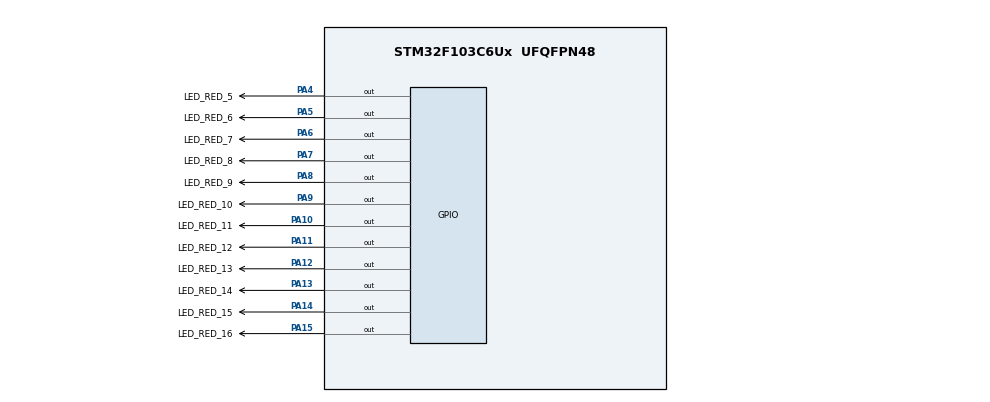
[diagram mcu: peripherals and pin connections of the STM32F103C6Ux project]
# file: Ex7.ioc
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Mcu.Family=STM32F1
Mcu.Name=STM32F103C6Ux
Mcu.Package=UFQFPN48
NVIC.PriorityGroup=NVIC_PRIORITYGROUP_4
PA10.GPIO_Label=LED_RED_11
PA10.Signal=GPIO_Output
PA11.GPIO_Label=LED_RED_12
PA11.Signal=GPIO_Output
PA12.GPIO_Label=LED_RED_13
PA12.Signal=GPIO_Output
PA13.GPIO_Label=LED_RED_14
PA13.Signal=GPIO_Output
PA14.GPIO_Label=LED_RED_15
PA14.Signal=GPIO_Output
PA15.GPIO_Label=LED_RED_16
PA15.Signal=GPIO_Output
PA4.GPIO_Label=LED_RED_5
PA4.Signal=GPIO_Output
PA5.GPIO_Label=LED_RED_6
PA5.Signal=GPIO_Output
PA6.GPIO_Label=LED_RED_7
PA6.Signal=GPIO_Output
PA7.GPIO_Label=LED_RED_8
PA7.Signal=GPIO_Output
PA8.GPIO_Label=LED_RED_9
PA8.Signal=GPIO_Output
PA9.GPIO_Label=LED_RED_10
PA9.Signal=GPIO_Output
ProjectManager.HeapSize=0x200
ProjectManager.StackSize=0x400
ProjectManager.TargetToolchain=STM32CubeIDE
RCC.APB1Freq_Value=8000000
RCC.APB2Freq_Value=8000000
VP_SYS_VS_ND.Mode=No_Debug
board=custom

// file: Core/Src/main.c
/* USER CODE BEGIN Header */
/**
  ******************************************************************************
  * @file           : main.c
  * @brief          : Main program body
  ******************************************************************************
  * @attention
  *
  * <h2><center>&copy; Copyright (c) 2024 STMicroelectronics.
  * All rights reserved.</center></h2>
  *
  * This software component is licensed by ST under BSD 3-Clause license,
  * the "License"; You may not use this file except in compliance with the
  * License. You may obtain a copy of the License at:
  *                        opensource.org/licenses/BSD-3-Clause
  *
  ******************************************************************************
  */
/* USER CODE END Header */
#include "main.h"

void SystemClock_Config(void);
static void MX_GPIO_Init(void);

void display12Led(int counter);
void clearAllClock();

int main(void)
{

  /* MCU Configuration--------------------------------------------------------*/

  /* Reset of all peripherals, Initializes the Flash interface and the Systick. */
  HAL_Init();

  /* Configure the system clock */
  SystemClock_Config();

  /* Initialize all configured peripherals */
  MX_GPIO_Init();

  /* Infinite loop */
  /* USER CODE BEGIN WHILE */
  int counter = 1;
  int limitNumber = 13;

  while (1)
  {
    /* USER CODE END WHILE */
	display12Led(counter);
	counter++;
	HAL_Delay(1000);
	if(counter == limitNumber){
		clearAllClock();
		counter = 1;
		HAL_Delay(1000);
	}
  }
}

void clearAllClock(){
	  HAL_GPIO_WritePin(LED_RED_5_GPIO_Port, LED_RED_5_Pin, GPIO_PIN_RESET);
	  HAL_GPIO_WritePin(LED_RED_6_GPIO_Port, LED_RED_6_Pin, GPIO_PIN_RESET);
	  HAL_GPIO_WritePin(LED_RED_7_GPIO_Port, LED_RED_7_Pin, GPIO_PIN_RESET);
	  HAL_GPIO_WritePin(LED_RED_8_GPIO_Port, LED_RED_8_Pin, GPIO_PIN_RESET);
	  HAL_GPIO_WritePin(LED_RED_9_GPIO_Port, LED_RED_9_Pin, GPIO_PIN_RESET);
	  HAL_GPIO_WritePin(LED_RED_10_GPIO_Port, LED_RED_10_Pin, GPIO_PIN_RESET);
	  HAL_GPIO_WritePin(LED_RED_11_GPIO_Port, LED_RED_11_Pin, GPIO_PIN_RESET);
	  HAL_GPIO_WritePin(LED_RED_12_GPIO_Port, LED_RED_12_Pin, GPIO_PIN_RESET);
	  HAL_GPIO_WritePin(LED_RED_13_GPIO_Port, LED_RED_13_Pin, GPIO_PIN_RESET);
	  HAL_GPIO_WritePin(LED_RED_14_GPIO_Port, LED_RED_14_Pin, GPIO_PIN_RESET);
	  HAL_GPIO_WritePin(LED_RED_15_GPIO_Port, LED_RED_15_Pin, GPIO_PIN_RESET);
	  HAL_GPIO_WritePin(LED_RED_16_GPIO_Port, LED_RED_16_Pin, GPIO_PIN_RESET);
}

void setNumberOnClock(int num){
	  if(counter == 1){
		  HAL_GPIO_WritePin(LED_RED_7_GPIO_Port, LED_RED_7_Pin, GPIO_PIN_SET);
	  }
	  if(counter == 2){
		  HAL_GPIO_WritePin(LED_RED_8_GPIO_Port, LED_RED_8_Pin, GPIO_PIN_SET);
	  }
	  if(counter == 3){
		  HAL_GPIO_WritePin(LED_RED_9_GPIO_Port, LED_RED_9_Pin, GPIO_PIN_SET);
	  }
	  if(counter == 4){
		  HAL_GPIO_WritePin(LED_RED_10_GPIO_Port, LED_RED_10_Pin, GPIO_PIN_SET);
	  }
	  if(counter == 5){
		  HAL_GPIO_WritePin(LED_RED_11_GPIO_Port, LED_RED_11_Pin, GPIO_PIN_SET);
	  }
	  if(counter == 6){
		  HAL_GPIO_WritePin(LED_RED_12_GPIO_Port, LED_RED_12_Pin, GPIO_PIN_SET);
	  }
	  if(counter == 7){
		  HAL_GPIO_WritePin(LED_RED_13_GPIO_Port, LED_RED_13_Pin, GPIO_PIN_SET);
	  }
	  if(counter == 8){
		  HAL_GPIO_WritePin(LED_RED_14_GPIO_Port, LED_RED_14_Pin, GPIO_PIN_SET);
	  }
	  if(counter == 9){
		  HAL_GPIO_WritePin(LED_RED_15_GPIO_Port, LED_RED_15_Pin, GPIO_PIN_SET);
	  }
	  if(counter == 10){
		  HAL_GPIO_WritePin(LED_RED_16_GPIO_Port, LED_RED_16_Pin, GPIO_PIN_SET);
	  }
	  if(counter == 11){
		  HAL_GPIO_WritePin(LED_RED_5_GPIO_Port, LED_RED_5_Pin, GPIO_PIN_SET);
	  }
	  if(counter == 12){
		  HAL_GPIO_WritePin(LED_RED_6_GPIO_Port, LED_RED_6_Pin, GPIO_PIN_SET);
	  }
}

void clearNumberOnClock(int num){
	  if(counter == 1){
		  HAL_GPIO_WritePin(LED_RED_7_GPIO_Port, LED_RED_7_Pin, GPIO_PIN_RESET);
	  }
	  if(counter == 2){
		  HAL_GPIO_WritePin(LED_RED_8_GPIO_Port, LED_RED_8_Pin, GPIO_PIN_RESET);
	  }
	  if(counter == 3){
		  HAL_GPIO_WritePin(LED_RED_9_GPIO_Port, LED_RED_9_Pin, GPIO_PIN_RESET);
	  }
	  if(counter == 4){
		  HAL_GPIO_WritePin(LED_RED_10_GPIO_Port, LED_RED_10_Pin, GPIO_PIN_RESET);
	  }
	  if(counter == 5){
		  HAL_GPIO_WritePin(LED_RED_11_GPIO_Port, LED_RED_11_Pin, GPIO_PIN_RESET);
	  }
	  if(counter == 6){
		  HAL_GPIO_WritePin(LED_RED_12_GPIO_Port, LED_RED_12_Pin, GPIO_PIN_RESET);
	  }
	  if(counter == 7){
		  HAL_GPIO_WritePin(LED_RED_13_GPIO_Port, LED_RED_13_Pin, GPIO_PIN_RESET);
	  }
	  if(counter == 8){
		  HAL_GPIO_WritePin(LED_RED_14_GPIO_Port, LED_RED_14_Pin, GPIO_PIN_RESET);
	  }
	  if(counter == 9){
		  HAL_GPIO_WritePin(LED_RED_15_GPIO_Port, LED_RED_15_Pin, GPIO_PIN_RESET);
	  }
	  if(counter == 10){
		  HAL_GPIO_WritePin(LED_RED_16_GPIO_Port, LED_RED_16_Pin, GPIO_PIN_RESET);
	  }
	  if(counter == 11){
		  HAL_GPIO_WritePin(LED_RED_5_GPIO_Port, LED_RED_5_Pin, GPIO_PIN_RESET);
	  }
	  if(counter == 12){
		  HAL_GPIO_WritePin(LED_RED_6_GPIO_Port, LED_RED_6_Pin, GPIO_PIN_RESET);
	  }
}

 void display12Led(int counter){

	  if(counter == 1){
		  HAL_GPIO_WritePin(LED_RED_5_GPIO_Port, LED_RED_5_Pin, GPIO_PIN_RESET);
		  HAL_GPIO_WritePin(LED_RED_6_GPIO_Port, LED_RED_6_Pin, GPIO_PIN_RESET);
		  HAL_GPIO_WritePin(LED_RED_7_GPIO_Port, LED_RED_7_Pin, GPIO_PIN_SET);
		  HAL_GPIO_WritePin(LED_RED_8_GPIO_Port, LED_RED_8_Pin, GPIO_PIN_RESET);
		  HAL_GPIO_WritePin(LED_RED_9_GPIO_Port, LED_RED_9_Pin, GPIO_PIN_RESET);
		  HAL_GPIO_WritePin(LED_RED_10_GPIO_Port, LED_RED_10_Pin, GPIO_PIN_RESET);
		  HAL_GPIO_WritePin(LED_RED_11_GPIO_Port, LED_RED_11_Pin, GPIO_PIN_RESET);
		  HAL_GPIO_WritePin(LED_RED_12_GPIO_Port, LED_RED_12_Pin, GPIO_PIN_RESET);
		  HAL_GPIO_WritePin(LED_RED_13_GPIO_Port, LED_RED_13_Pin, GPIO_PIN_RESET);
		  HAL_GPIO_WritePin(LED_RED_14_GPIO_Port, LED_RED_14_Pin, GPIO_PIN_RESET);
		  HAL_GPIO_WritePin(LED_RED_15_GPIO_Port, LED_RED_15_Pin, GPIO_PIN_RESET);
		  HAL_GPIO_WritePin(LED_RED_16_GPIO_Port, LED_RED_16_Pin, GPIO_PIN_RESET);
	  }
	  if(counter == 2){
		  HAL_GPIO_WritePin(LED_RED_5_GPIO_Port, LED_RED_5_Pin, GPIO_PIN_RESET);
		  HAL_GPIO_WritePin(LED_RED_6_GPIO_Port, LED_RED_6_Pin, GPIO_PIN_RESET);
		  HAL_GPIO_WritePin(LED_RED_7_GPIO_Port, LED_RED_7_Pin, GPIO_PIN_SET);
		  HAL_GPIO_WritePin(LED_RED_8_GPIO_Port, LED_RED_8_Pin, GPIO_PIN_SET);
		  HAL_GPIO_WritePin(LED_RED_9_GPIO_Port, LED_RED_9_Pin, GPIO_PIN_RESET);
		  HAL_GPIO_WritePin(LED_RED_10_GPIO_Port, LED_RED_10_Pin, GPIO_PIN_RESET);
		  HAL_GPIO_WritePin(LED_RED_11_GPIO_Port, LED_RED_11_Pin, GPIO_PIN_RESET);
		  HAL_GPIO_WritePin(LED_RED_12_GPIO_Port, LED_RED_12_Pin, GPIO_PIN_RESET);
		  HAL_GPIO_WritePin(LED_RED_13_GPIO_Port, LED_RED_13_Pin, GPIO_PIN_RESET);
		  HAL_GPIO_WritePin(LED_RED_14_GPIO_Port, LED_RED_14_Pin, GPIO_PIN_RESET);
		  HAL_GPIO_WritePin(LED_RED_15_GPIO_Port, LED_RED_15_Pin, GPIO_PIN_RESET);
		  HAL_GPIO_WritePin(LED_RED_16_GPIO_Port, LED_RED_16_Pin, GPIO_PIN_RESET);
	  }
	  if(counter == 3){
		  HAL_GPIO_WritePin(LED_RED_5_GPIO_Port, LED_RED_5_Pin, GPIO_PIN_RESET);
		  HAL_GPIO_WritePin(LED_RED_6_GPIO_Port, LED_RED_6_Pin, GPIO_PIN_RESET);
		  HAL_GPIO_WritePin(LED_RED_7_GPIO_Port, LED_RED_7_Pin, GPIO_PIN_SET);
		  HAL_GPIO_WritePin(LED_RED_8_GPIO_Port, LED_RED_8_Pin, GPIO_PIN_SET);
		  HAL_GPIO_WritePin(LED_RED_9_GPIO_Port, LED_RED_9_Pin, GPIO_PIN_SET);
		  HAL_GPIO_WritePin(LED_RED_10_GPIO_Port, LED_RED_10_Pin, GPIO_PIN_RESET);
		  HAL_GPIO_WritePin(LED_RED_11_GPIO_Port, LED_RED_11_Pin, GPIO_PIN_RESET);
		  HAL_GPIO_WritePin(LED_RED_12_GPIO_Port, LED_RED_12_Pin, GPIO_PIN_RESET);
		  HAL_GPIO_WritePin(LED_RED_13_GPIO_Port, LED_RED_13_Pin, GPIO_PIN_RESET);
		  HAL_GPIO_WritePin(LED_RED_14_GPIO_Port, LED_RED_14_Pin, GPIO_PIN_RESET);
		  HAL_GPIO_WritePin(LED_RED_15_GPIO_Port, LED_RED_15_Pin, GPIO_PIN_RESET);
		  HAL_GPIO_WritePin(LED_RED_16_GPIO_Port, LED_RED_16_Pin, GPIO_PIN_RESET);
	  }
	  if(counter == 4){
		  HAL_GPIO_WritePin(LED_RED_5_GPIO_Port, LED_RED_5_Pin, GPIO_PIN_RESET);
		  HAL_GPIO_WritePin(LED_RED_6_GPIO_Port, LED_RED_6_Pin, GPIO_PIN_RESET);
		  HAL_GPIO_WritePin(LED_RED_7_GPIO_Port, LED_RED_7_Pin, GPIO_PIN_SET);
		  HAL_GPIO_WritePin(LED_RED_8_GPIO_Port, LED_RED_8_Pin, GPIO_PIN_SET);
		  HAL_GPIO_WritePin(LED_RED_9_GPIO_Port, LED_RED_9_Pin, GPIO_PIN_SET);
		  HAL_GPIO_WritePin(LED_RED_10_GPIO_Port, LED_RED_10_Pin, GPIO_PIN_SET);
		  HAL_GPIO_WritePin(LED_RED_11_GPIO_Port, LED_RED_11_Pin, GPIO_PIN_RESET);
		  HAL_GPIO_WritePin(LED_RED_12_GPIO_Port, LED_RED_12_Pin, GPIO_PIN_RESET);
		  HAL_GPIO_WritePin(LED_RED_13_GPIO_Port, LED_RED_13_Pin, GPIO_PIN_RESET);
		  HAL_GPIO_WritePin(LED_RED_14_GPIO_Port, LED_RED_14_Pin, GPIO_PIN_RESET);
		  HAL_GPIO_WritePin(LED_RED_15_GPIO_Port, LED_RED_15_Pin, GPIO_PIN_RESET);
		  HAL_GPIO_WritePin(LED_RED_16_GPIO_Port, LED_RED_16_Pin, GPIO_PIN_RESET);
	  }
	  if(counter == 5){
		  HAL_GPIO_WritePin(LED_RED_5_GPIO_Port, LED_RED_5_Pin, GPIO_PIN_RESET);
		  HAL_GPIO_WritePin(LED_RED_6_GPIO_Port, LED_RED_6_Pin, GPIO_PIN_RESET);
		  HAL_GPIO_WritePin(LED_RED_7_GPIO_Port, LED_RED_7_Pin, GPIO_PIN_SET);
		  HAL_GPIO_WritePin(LED_RED_8_GPIO_Port, LED_RED_8_Pin, GPIO_PIN_SET);
		  HAL_GPIO_WritePin(LED_RED_9_GPIO_Port, LED_RED_9_Pin, GPIO_PIN_SET);
		  HAL_GPIO_WritePin(LED_RED_10_GPIO_Port, LED_RED_10_Pin, GPIO_PIN_SET);
		  HAL_GPIO_WritePin(LED_RED_11_GPIO_Port, LED_RED_11_Pin, GPIO_PIN_SET);
		  HAL_GPIO_WritePin(LED_RED_12_GPIO_Port, LED_RED_12_Pin, GPIO_PIN_RESET);
		  HAL_GPIO_WritePin(LED_RED_13_GPIO_Port, LED_RED_13_Pin, GPIO_PIN_RESET);
		  HAL_GPIO_WritePin(LED_RED_14_GPIO_Port, LED_RED_14_Pin, GPIO_PIN_RESET);
		  HAL_GPIO_WritePin(LED_RED_15_GPIO_Port, LED_RED_15_Pin, GPIO_PIN_RESET);
		  HAL_GPIO_WritePin(LED_RED_16_GPIO_Port, LED_RED_16_Pin, GPIO_PIN_RESET);
	  }
	  if(counter == 6){
		  HAL_GPIO_WritePin(LED_RED_5_GPIO_Port, LED_RED_5_Pin, GPIO_PIN_RESET);
		  HAL_GPIO_WritePin(LED_RED_6_GPIO_Port, LED_RED_6_Pin, GPIO_PIN_RESET);
		  HAL_GPIO_WritePin(LED_RED_7_GPIO_Port, LED_RED_7_Pin, GPIO_PIN_SET);
		  HAL_GPIO_WritePin(LED_RED_8_GPIO_Port, LED_RED_8_Pin, GPIO_PIN_SET);
		  HAL_GPIO_WritePin(LED_RED_9_GPIO_Port, LED_RED_9_Pin, GPIO_PIN_SET);
		  HAL_GPIO_WritePin(LED_RED_10_GPIO_Port, LED_RED_10_Pin, GPIO_PIN_SET);
		  HAL_GPIO_WritePin(LED_RED_11_GPIO_Port, LED_RED_11_Pin, GPIO_PIN_SET);
		  HAL_GPIO_WritePin(LED_RED_12_GPIO_Port, LED_RED_12_Pin, GPIO_PIN_SET);
		  HAL_GPIO_WritePin(LED_RED_13_GPIO_Port, LED_RED_13_Pin, GPIO_PIN_RESET);
		  HAL_GPIO_WritePin(LED_RED_14_GPIO_Port, LED_RED_14_Pin, GPIO_PIN_RESET);
		  HAL_GPIO_WritePin(LED_RED_15_GPIO_Port, LED_RED_15_Pin, GPIO_PIN_RESET);
		  HAL_GPIO_WritePin(LED_RED_16_GPIO_Port, LED_RED_16_Pin, GPIO_PIN_RESET);
	  }
	  if(counter == 7){
		  HAL_GPIO_WritePin(LED_RED_5_GPIO_Port, LED_RED_5_Pin, GPIO_PIN_RESET);
		  HAL_GPIO_WritePin(LED_RED_6_GPIO_Port, LED_RED_6_Pin, GPIO_PIN_RESET);
		  HAL_GPIO_WritePin(LED_RED_7_GPIO_Port, LED_RED_7_Pin, GPIO_PIN_SET);
		  HAL_GPIO_WritePin(LED_RED_8_GPIO_Port, LED_RED_8_Pin, GPIO_PIN_SET);
		  HAL_GPIO_WritePin(LED_RED_9_GPIO_Port, LED_RED_9_Pin, GPIO_PIN_SET);
		  HAL_GPIO_WritePin(LED_RED_10_GPIO_Port, LED_RED_10_Pin, GPIO_PIN_SET);
		  HAL_GPIO_WritePin(LED_RED_11_GPIO_Port, LED_RED_11_Pin, GPIO_PIN_SET);
		  HAL_GPIO_WritePin(LED_RED_12_GPIO_Port, LED_RED_12_Pin, GPIO_PIN_SET);
		  HAL_GPIO_WritePin(LED_RED_13_GPIO_Port, LED_RED_13_Pin, GPIO_PIN_SET);
		  HAL_GPIO_WritePin(LED_RED_14_GPIO_Port, LED_RED_14_Pin, GPIO_PIN_RESET);
		  HAL_GPIO_WritePin(LED_RED_15_GPIO_Port, LED_RED_15_Pin, GPIO_PIN_RESET);
		  HAL_GPIO_WritePin(LED_RED_16_GPIO_Port, LED_RED_16_Pin, GPIO_PIN_RESET);
	  }
	  if(counter == 8){
		  HAL_GPIO_WritePin(LED_RED_5_GPIO_Port, LED_RED_5_Pin, GPIO_PIN_RESET);
		  HAL_GPIO_WritePin(LED_RED_6_GPIO_Port, LED_RED_6_Pin, GPIO_PIN_RESET);
		  HAL_GPIO_WritePin(LED_RED_7_GPIO_Port, LED_RED_7_Pin, GPIO_PIN_SET);
		  HAL_GPIO_WritePin(LED_RED_8_GPIO_Port, LED_RED_8_Pin, GPIO_PIN_SET);
		  HAL_GPIO_WritePin(LED_RED_9_GPIO_Port, LED_RED_9_Pin, GPIO_PIN_SET);
		  HAL_GPIO_WritePin(LED_RED_10_GPIO_Port, LED_RED_10_Pin, GPIO_PIN_SET);
		  HAL_GPIO_WritePin(LED_RED_11_GPIO_Port, LED_RED_11_Pin, GPIO_PIN_SET);
		  HAL_GPIO_WritePin(LED_RED_12_GPIO_Port, LED_RED_12_Pin, GPIO_PIN_SET);
		  HAL_GPIO_WritePin(LED_RED_13_GPIO_Port, LED_RED_13_Pin, GPIO_PIN_SET);
		  HAL_GPIO_WritePin(LED_RED_14_GPIO_Port, LED_RED_14_Pin, GPIO_PIN_SET);
		  HAL_GPIO_WritePin(LED_RED_15_GPIO_Port, LED_RED_15_Pin, GPIO_PIN_RESET);
		  HAL_GPIO_WritePin(LED_RED_16_GPIO_Port, LED_RED_16_Pin, GPIO_PIN_RESET);
	  }
	  if(counter == 9){
		  HAL_GPIO_WritePin(LED_RED_5_GPIO_Port, LED_RED_5_Pin, GPIO_PIN_RESET);
		  HAL_GPIO_WritePin(LED_RED_6_GPIO_Port, LED_RED_6_Pin, GPIO_PIN_RESET);
		  HAL_GPIO_WritePin(LED_RED_7_GPIO_Port, LED_RED_7_Pin, GPIO_PIN_SET);
		  HAL_GPIO_WritePin(LED_RED_8_GPIO_Port, LED_RED_8_Pin, GPIO_PIN_SET);
		  HAL_GPIO_WritePin(LED_RED_9_GPIO_Port, LED_RED_9_Pin, GPIO_PIN_SET);
		  HAL_GPIO_WritePin(LED_RED_10_GPIO_Port, LED_RED_10_Pin, GPIO_PIN_SET);
		  HAL_GPIO_WritePin(LED_RED_11_GPIO_Port, LED_RED_11_Pin, GPIO_PIN_SET);
		  HAL_GPIO_WritePin(LED_RED_12_GPIO_Port, LED_RED_12_Pin, GPIO_PIN_SET);
		  HAL_GPIO_WritePin(LED_RED_13_GPIO_Port, LED_RED_13_Pin, GPIO_PIN_SET);
		  HAL_GPIO_WritePin(LED_RED_14_GPIO_Port, LED_RED_14_Pin, GPIO_PIN_SET);
		  HAL_GPIO_WritePin(LED_RED_15_GPIO_Port, LED_RED_15_Pin, GPIO_PIN_SET);
		  HAL_GPIO_WritePin(LED_RED_16_GPIO_Port, LED_RED_16_Pin, GPIO_PIN_RESET);
	  }
	  if(counter == 10){
		  HAL_GPIO_WritePin(LED_RED_5_GPIO_Port, LED_RED_5_Pin, GPIO_PIN_RESET);
		  HAL_GPIO_WritePin(LED_RED_6_GPIO_Port, LED_RED_6_Pin, GPIO_PIN_RESET);
		  HAL_GPIO_WritePin(LED_RED_7_GPIO_Port, LED_RED_7_Pin, GPIO_PIN_SET);
		  HAL_GPIO_WritePin(LED_RED_8_GPIO_Port, LED_RED_8_Pin, GPIO_PIN_SET);
		  HAL_GPIO_WritePin(LED_RED_9_GPIO_Port, LED_RED_9_Pin, GPIO_PIN_SET);
		  HAL_GPIO_WritePin(LED_RED_10_GPIO_Port, LED_RED_10_Pin, GPIO_PIN_SET);
		  HAL_GPIO_WritePin(LED_RED_11_GPIO_Port, LED_RED_11_Pin, GPIO_PIN_SET);
		  HAL_GPIO_WritePin(LED_RED_12_GPIO_Port, LED_RED_12_Pin, GPIO_PIN_SET);
		  HAL_GPIO_WritePin(LED_RED_13_GPIO_Port, LED_RED_13_Pin, GPIO_PIN_SET);
		  HAL_GPIO_WritePin(LED_RED_14_GPIO_Port, LED_RED_14_Pin, GPIO_PIN_SET);
		  HAL_GPIO_WritePin(LED_RED_15_GPIO_Port, LED_RED_15_Pin, GPIO_PIN_SET);
		  HAL_GPIO_WritePin(LED_RED_16_GPIO_Port, LED_RED_16_Pin, GPIO_PIN_SET);
	  }
	  if(counter == 11){
		  HAL_GPIO_WritePin(LED_RED_5_GPIO_Port, LED_RED_5_Pin, GPIO_PIN_SET);
		  HAL_GPIO_WritePin(LED_RED_6_GPIO_Port, LED_RED_6_Pin, GPIO_PIN_RESET);
		  HAL_GPIO_WritePin(LED_RED_7_GPIO_Port, LED_RED_7_Pin, GPIO_PIN_SET);
		  HAL_GPIO_WritePin(LED_RED_8_GPIO_Port, LED_RED_8_Pin, GPIO_PIN_SET);
		  HAL_GPIO_WritePin(LED_RED_9_GPIO_Port, LED_RED_9_Pin, GPIO_PIN_SET);
		  HAL_GPIO_WritePin(LED_RED_10_GPIO_Port, LED_RED_10_Pin, GPIO_PIN_SET);
		  HAL_GPIO_WritePin(LED_RED_11_GPIO_Port, LED_RED_11_Pin, GPIO_PIN_SET);
		  HAL_GPIO_WritePin(LED_RED_12_GPIO_Port, LED_RED_12_Pin, GPIO_PIN_SET);
		  HAL_GPIO_WritePin(LED_RED_13_GPIO_Port, LED_RED_13_Pin, GPIO_PIN_SET);
		  HAL_GPIO_WritePin(LED_RED_14_GPIO_Port, LED_RED_14_Pin, GPIO_PIN_SET);
		  HAL_GPIO_WritePin(LED_RED_15_GPIO_Port, LED_RED_15_Pin, GPIO_PIN_SET);
		  HAL_GPIO_WritePin(LED_RED_16_GPIO_Port, LED_RED_16_Pin, GPIO_PIN_SET);
	  }
	  if(counter == 12){
		  HAL_GPIO_WritePin(LED_RED_5_GPIO_Port, LED_RED_5_Pin, GPIO_PIN_SET);
		  HAL_GPIO_WritePin(LED_RED_6_GPIO_Port, LED_RED_6_Pin, GPIO_PIN_SET);
		  HAL_GPIO_WritePin(LED_RED_7_GPIO_Port, LED_RED_7_Pin, GPIO_PIN_SET);
		  HAL_GPIO_WritePin(LED_RED_8_GPIO_Port, LED_RED_8_Pin, GPIO_PIN_SET);
		  HAL_GPIO_WritePin(LED_RED_9_GPIO_Port, LED_RED_9_Pin, GPIO_PIN_SET);
		  HAL_GPIO_WritePin(LED_RED_10_GPIO_Port, LED_RED_10_Pin, GPIO_PIN_SET);
		  HAL_GPIO_WritePin(LED_RED_11_GPIO_Port, LED_RED_11_Pin, GPIO_PIN_SET);
		  HAL_GPIO_WritePin(LED_RED_12_GPIO_Port, LED_RED_12_Pin, GPIO_PIN_SET);
		  HAL_GPIO_WritePin(LED_RED_13_GPIO_Port, LED_RED_13_Pin, GPIO_PIN_SET);
		  HAL_GPIO_WritePin(LED_RED_14_GPIO_Port, LED_RED_14_Pin, GPIO_PIN_SET);
		  HAL_GPIO_WritePin(LED_RED_15_GPIO_Port, LED_RED_15_Pin, GPIO_PIN_SET);
		  HAL_GPIO_WritePin(LED_RED_16_GPIO_Port, LED_RED_16_Pin, GPIO_PIN_SET);
	  }

  }

void SystemClock_Config(void)
{
  RCC_OscInitTypeDef RCC_OscInitStruct = {0};
  RCC_ClkInitTypeDef RCC_ClkInitStruct = {0};

  /** Initializes the RCC Oscillators according to the specified parameters
  * in the RCC_OscInitTypeDef structure.
  */
  RCC_OscInitStruct.OscillatorType = RCC_OSCILLATORTYPE_HSI;
  RCC_OscInitStruct.HSIState = RCC_HSI_ON;
  RCC_OscInitStruct.HSICalibrationValue = RCC_HSICALIBRATION_DEFAULT;
  RCC_OscInitStruct.PLL.PLLState = RCC_PLL_NONE;
  if (HAL_RCC_OscConfig(&RCC_OscInitStruct) != HAL_OK)
  {
    Error_Handler();
  }
  /** Initializes the CPU, AHB and APB buses clocks
  */
  RCC_ClkInitStruct.ClockType = RCC_CLOCKTYPE_HCLK|RCC_CLOCKTYPE_SYSCLK
                              |RCC_CLOCKTYPE_PCLK1|RCC_CLOCKTYPE_PCLK2;
  RCC_ClkInitStruct.SYSCLKSource = RCC_SYSCLKSOURCE_HSI;
  RCC_ClkInitStruct.AHBCLKDivider = RCC_SYSCLK_DIV1;
  RCC_ClkInitStruct.APB1CLKDivider = RCC_HCLK_DIV1;
  RCC_ClkInitStruct.APB2CLKDivider = RCC_HCLK_DIV1;

  if (HAL_RCC_ClockConfig(&RCC_ClkInitStruct, FLASH_LATENCY_0) != HAL_OK)
  {
    Error_Handler();
  }
}

static void MX_GPIO_Init(void)
{
  GPIO_InitTypeDef GPIO_InitStruct = {0};

  /* GPIO Ports Clock Enable */
  __HAL_RCC_GPIOA_CLK_ENABLE();

  /*Configure GPIO pin Output Level */
  HAL_GPIO_WritePin(GPIOA, LED_RED_5_Pin|LED_RED_6_Pin|LED_RED_7_Pin|LED_RED_8_Pin
                          |LED_RED_9_Pin|LED_RED_10_Pin|LED_RED_11_Pin|LED_RED_12_Pin
                          |LED_RED_13_Pin|LED_RED_14_Pin|LED_RED_15_Pin|LED_RED_16_Pin, GPIO_PIN_RESET);

  /*Configure GPIO pins : LED_RED_5_Pin LED_RED_6_Pin LED_RED_7_Pin LED_RED_8_Pin
                           LED_RED_9_Pin LED_RED_10_Pin LED_RED_11_Pin LED_RED_12_Pin
                           LED_RED_13_Pin LED_RED_14_Pin LED_RED_15_Pin LED_RED_16_Pin */
  GPIO_InitStruct.Pin = LED_RED_5_Pin|LED_RED_6_Pin|LED_RED_7_Pin|LED_RED_8_Pin
                          |LED_RED_9_Pin|LED_RED_10_Pin|LED_RED_11_Pin|LED_RED_12_Pin
                          |LED_RED_13_Pin|LED_RED_14_Pin|LED_RED_15_Pin|LED_RED_16_Pin;
  GPIO_InitStruct.Mode = GPIO_MODE_OUTPUT_PP;
  GPIO_InitStruct.Pull = GPIO_NOPULL;
  GPIO_InitStruct.Speed = GPIO_SPEED_FREQ_LOW;
  HAL_GPIO_Init(GPIOA, &GPIO_InitStruct);

}

void Error_Handler(void)
{
  __disable_irq();
  while (1)
  {
  }
}

/************************ (C) COPYRIGHT STMicroelectronics *****END OF FILE****/
